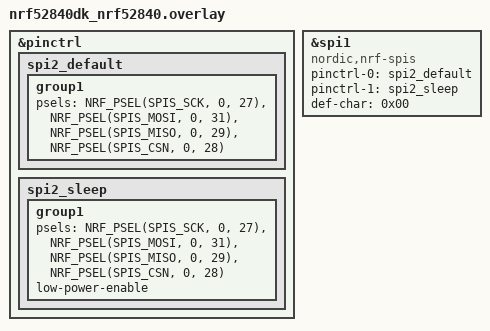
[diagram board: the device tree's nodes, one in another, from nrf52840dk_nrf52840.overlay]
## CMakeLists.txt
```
#
# Copyright (c) 2020 Nordic Semiconductor
#
# SPDX-License-Identifier: LicenseRef-BSD-5-Clause-Nordic
#

cmake_minimum_required(VERSION 3.8.2)

if (EXISTS "${CMAKE_CURRENT_SOURCE_DIR}/spm.conf")
  set(spm_CONF_FILE
    prj.conf
    ${CMAKE_CURRENT_LIST_DIR}/spm.conf
  )
endif()

if (EXISTS "${CMAKE_CURRENT_SOURCE_DIR}/mcuboot.conf")
  set(mcuboot_CONF_FILE
    prj.conf
    ${CMAKE_CURRENT_LIST_DIR}/mcuboot.conf
  )
endif()

if (EXISTS "${CMAKE_CURRENT_SOURCE_DIR}/${BOARD}.overlay")
  set(mcuboot_DTC_OVERLAY_FILE "${CMAKE_CURRENT_SOURCE_DIR}/${BOARD}.overlay")
endif()

find_package(Zephyr REQUIRED HINTS $ENV{ZEPHYR_BASE})
project(empty_app_core)

target_sources(app PRIVATE src/main.c)
```

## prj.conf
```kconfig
#
# Copyright (c) 2020 Nordic Semiconductor ASA
#
# SPDX-License-Identifier: LicenseRef-BSD-5-Clause-Nordic
#
# CONFIG_BOARD_ENABLE_CPUNET=y
CONFIG_SPI=y
CONFIG_MAIN_STACK_SIZE=4096
CONFIG_SPI_SLAVE=y

CONFIG_DEBUG_OPTIMIZATIONS=y
```

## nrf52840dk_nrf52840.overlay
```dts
&pinctrl {
	spi2_default: spi2_default {
		group1 {
			psels = <NRF_PSEL(SPIS_SCK, 0, 27)>,
					<NRF_PSEL(SPIS_MOSI, 0, 31)>,
					<NRF_PSEL(SPIS_MISO, 0, 29)>,
					<NRF_PSEL(SPIS_CSN, 0, 28)>;
		};
	};

	spi2_sleep: spi2_sleep {
		group1 {
			psels = <NRF_PSEL(SPIS_SCK, 0, 27)>,
					<NRF_PSEL(SPIS_MOSI, 0, 31)>,
					<NRF_PSEL(SPIS_MISO, 0, 29)>,
					<NRF_PSEL(SPIS_CSN, 0, 28)>;
			low-power-enable;
		};
	};
};

my_spi_slave: &spi1 {
	compatible = "nordic,nrf-spis";
	status = "okay";
	pinctrl-0 = <&spi2_default>;
	pinctrl-1 = <&spi2_sleep>;
	//sck-pin = <27>;
	//mosi-pin = <31>;
	//miso-pin = <29>;
	//csn-pin = <28>;
	def-char = <0x00>;
};
```

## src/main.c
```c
/*
* Copyright (c) 2012-2014 Wind River Systems, Inc.
*
* SPDX-License-Identifier: Apache-2.0
*/

#include <zephyr.h>
#include <sys/printk.h>
#include <drivers/spi.h>

#define DT_DRV_COMPAT nordic_nrf_spis

static const struct spi_config spi_cfg = {
	.operation = SPI_WORD_SET(8) | SPI_TRANSFER_MSB | SPI_OP_MODE_SLAVE |
		     SPI_MODE_CPOL | SPI_MODE_CPHA,
	.frequency = 4000000,
	.slave = 1,
};

const struct device *spi_dev;

#define SPIS_STACK_SIZE 500
#define SPIS_PRIORITY 5

extern void spis_thread(void *, void *, void *);

#define MY_SPI_SLAVE			DT_LABEL(DT_NODELABEL(my_spi_slave))

K_THREAD_DEFINE(spis_tid, SPIS_STACK_SIZE, spis_thread, NULL, NULL, NULL,
		SPIS_PRIORITY, 0, 0);

static void spi_init(void)
{
	spi_dev = device_get_binding(MY_SPI_SLAVE);//DT_LABEL(DT_DRV_INST(0)));

	//printk("Device name: %s\n", DT_LABEL(DT_DRV_INST(0)));

	if (spi_dev == NULL) {
		printk("Could not get %s device\n", DT_LABEL(DT_DRV_INST(0)));
		return;
	}

	/*printk("SPI CSN %d, MISO %d, MOSI %d, CLK %d\n",
	       DT_PROP(DT_DRV_INST(0), csn_pin),
	       DT_PROP(DT_DRV_INST(0), miso_pin),
	       DT_PROP(DT_DRV_INST(0), mosi_pin),
	       DT_PROP(DT_DRV_INST(0), sck_pin));*/
}

void spi_test_transceive(void)
{
	int err;
	static uint8_t tx_buffer[32] = { 's', 'p', 'i', 's', 'l',
					 'a', 'v', 'e', '\n' };
	static uint8_t rx_buffer[32];

	const struct spi_buf tx_buf = { .buf = tx_buffer,
					.len = sizeof(tx_buffer) };
	const struct spi_buf_set tx = { .buffers = &tx_buf, .count = 1 };

	struct spi_buf rx_buf = {
		.buf = rx_buffer,
		.len = sizeof(rx_buffer),
	};
	const struct spi_buf_set rx = { .buffers = &rx_buf, .count = 1 };

	err = spi_transceive(spi_dev, &spi_cfg, &tx, &rx);
	if (err < 0) {
		printk("SPI error: %d\n", err);
	} else {		
		printk("byte received: %d\n", err);
		printk("TX buffer [0]: %x\n", tx_buffer[0]);
		printk("RX buffer [0]: %x\n", rx_buffer[0]);
		tx_buffer[0]++;
	}
}

extern void spis_thread(void *unused1, void *unused2, void *unused3)
{
	spi_init();

	while (1) {
		spi_test_transceive();
	}
}

void main(void)
{
	printk("SPIS Example\n");
	printk("Add any handling you'd like in the main thread\n");
	printk("SPIS handling will be performed in an own thread\n");
}
```
